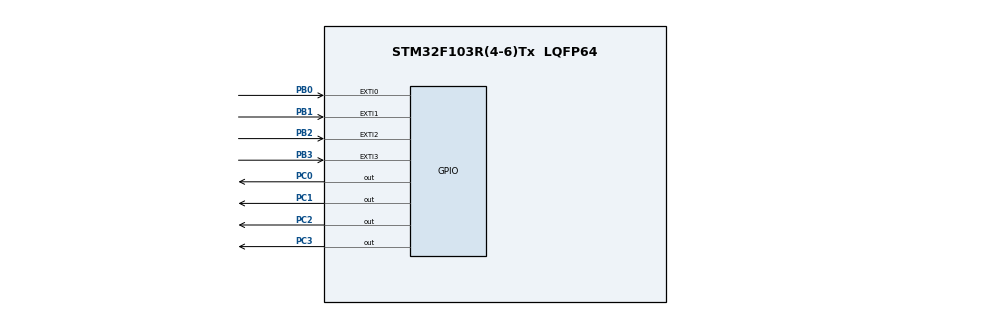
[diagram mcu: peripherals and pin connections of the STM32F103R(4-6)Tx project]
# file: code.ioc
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Mcu.Family=STM32F1
FREERTOS.Tasks01=defaultTask,24,128,StartDefaultTask,Default,NULL,Dynamic,NULL,NULL
PC2.Signal=GPIO_Output
NVIC.EXTI3_IRQn=true\:5\:0\:false\:false\:true\:true\:true\:true
PC0.GPIO_ModeDefaultOutputPP=GPIO_MODE_OUTPUT_PP
NVIC.TIM1_UP_IRQn=true\:0\:0\:false\:false\:true\:false\:false\:true
PC2.GPIO_Speed=GPIO_SPEED_FREQ_LOW
PB3.GPIO_ModeDefaultEXTI=GPIO_MODE_IT_RISING
PC0.Signal=GPIO_Output
VP_SYS_VS_ND.Mode=No_Debug
PC3.GPIO_Speed=GPIO_SPEED_FREQ_LOW
ProjectManager.StackSize=0x400
PC3.PinState=GPIO_PIN_RESET
VP_FREERTOS_VS_CMSIS_V2.Mode=CMSIS_V2
PB2.GPIO_ModeDefaultEXTI=GPIO_MODE_IT_RISING
NVIC.EXTI1_IRQn=true\:5\:0\:false\:false\:true\:true\:true\:true
PC0.GPIO_Speed=GPIO_SPEED_FREQ_LOW
ProjectManager.TargetToolchain=Makefile
PB1.GPIO_PuPd=GPIO_NOPULL
PB1.GPIO_ModeDefaultEXTI=GPIO_MODE_IT_RISING
PC3.Signal=GPIO_Output
PC1.PinState=GPIO_PIN_RESET
PB2.Signal=GPXTI2
board=custom
PC1.GPIO_PuPd=GPIO_PULLDOWN
PB0.GPIO_ModeDefaultEXTI=GPIO_MODE_IT_RISING
RCC.APB2Freq_Value=8000000
PB3.GPIO_PuPd=GPIO_NOPULL
VP_SYS_VS_tim1.Mode=TIM1
PC1.GPIO_Speed=GPIO_SPEED_FREQ_LOW
PC2.GPIO_PuPd=GPIO_PULLDOWN
Mcu.Name=STM32F103R(4-6)Tx
PB2.GPIO_PuPd=GPIO_NOPULL
PB3.Signal=GPXTI3
NVIC.EXTI0_IRQn=true\:5\:0\:true\:false\:true\:true\:true\:true
Mcu.Package=LQFP64
PB1.Signal=GPXTI1
NVIC.TimeBase=TIM1_UP_IRQn
PC2.PinState=GPIO_PIN_RESET
NVIC.TimeBaseIP=TIM1
ProjectManager.HeapSize=0x200
PC1.GPIO_ModeDefaultOutputPP=GPIO_MODE_OUTPUT_PP
NVIC.PriorityGroup=NVIC_PRIORITYGROUP_4
NVIC.EXTI2_IRQn=true\:5\:0\:false\:false\:true\:true\:true\:true
PC2.GPIO_ModeDefaultOutputPP=GPIO_MODE_OUTPUT_PP
PC3.GPIO_ModeDefaultOutputPP=GPIO_MODE_OUTPUT_PP
PC0.GPIO_PuPd=GPIO_PULLDOWN
RCC.APB1Freq_Value=8000000
PB0.Signal=GPXTI0
PC0.PinState=GPIO_PIN_RESET
PC1.Signal=GPIO_Output
PB0.GPIO_PuPd=GPIO_NOPULL
PC3.GPIO_PuPd=GPIO_PULLDOWN

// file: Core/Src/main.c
/* USER CODE BEGIN Header */
/**
  ******************************************************************************
  * @file           : main.c
  * @brief          : Main program body
  ******************************************************************************
  * @attention
  *
  * <h2><center>&copy; Copyright (c) 2020 STMicroelectronics.
  * All rights reserved.</center></h2>
  *
  * This software component is licensed by ST under Ultimate Liberty license
  * SLA0044, the "License"; You may not use this file except in compliance with
  * the License. You may obtain a copy of the License at:
  *                             www.st.com/SLA0044
  *
  ******************************************************************************
  */
/* USER CODE END Header */
#include "main.h"
#include "cmsis_os.h"
#include "gpio.h"

void SystemClock_Config(void);
void MX_FREERTOS_Init(void);

int main(void)
{

  /* MCU Configuration--------------------------------------------------------*/

  /* Reset of all peripherals, Initializes the Flash interface and the Systick. */
  HAL_Init();

  /* Configure the system clock */
  SystemClock_Config();

  /* Initialize all configured peripherals */
  MX_GPIO_Init();

  /* Init scheduler */
  osKernelInitialize();  /* Call init function for freertos objects (in freertos.c) */
  MX_FREERTOS_Init();
  /* Start scheduler */
  osKernelStart();

  /* We should never get here as control is now taken by the scheduler */
  /* Infinite loop */
  while (1)
  {

  }
}

void SystemClock_Config(void)
{
  RCC_OscInitTypeDef RCC_OscInitStruct = {0};
  RCC_ClkInitTypeDef RCC_ClkInitStruct = {0};

  /** Initializes the RCC Oscillators according to the specified parameters
  * in the RCC_OscInitTypeDef structure.
  */
  RCC_OscInitStruct.OscillatorType = RCC_OSCILLATORTYPE_HSI;
  RCC_OscInitStruct.HSIState = RCC_HSI_ON;
  RCC_OscInitStruct.HSICalibrationValue = RCC_HSICALIBRATION_DEFAULT;
  RCC_OscInitStruct.PLL.PLLState = RCC_PLL_NONE;
  if (HAL_RCC_OscConfig(&RCC_OscInitStruct) != HAL_OK)
  {
    Error_Handler();
  }
  /** Initializes the CPU, AHB and APB buses clocks
  */
  RCC_ClkInitStruct.ClockType = RCC_CLOCKTYPE_HCLK|RCC_CLOCKTYPE_SYSCLK
                              |RCC_CLOCKTYPE_PCLK1|RCC_CLOCKTYPE_PCLK2;
  RCC_ClkInitStruct.SYSCLKSource = RCC_SYSCLKSOURCE_HSI;
  RCC_ClkInitStruct.AHBCLKDivider = RCC_SYSCLK_DIV1;
  RCC_ClkInitStruct.APB1CLKDivider = RCC_HCLK_DIV1;
  RCC_ClkInitStruct.APB2CLKDivider = RCC_HCLK_DIV1;

  if (HAL_RCC_ClockConfig(&RCC_ClkInitStruct, FLASH_LATENCY_0) != HAL_OK)
  {
    Error_Handler();
  }
}

 /**
  * @brief  Period elapsed callback in non blocking mode
  * @note   This function is called  when TIM1 interrupt took place, inside
  * HAL_TIM_IRQHandler(). It makes a direct call to HAL_IncTick() to increment
  * a global variable "uwTick" used as application time base.
  * @param  htim : TIM handle
  * @retval None
  */
void HAL_TIM_PeriodElapsedCallback(TIM_HandleTypeDef *htim)
{
  if (htim->Instance == TIM1) {
    HAL_IncTick();
  }
}

void Error_Handler(void)
{
  __disable_irq();
  while (1)
  {
  }
}

/************************ (C) COPYRIGHT STMicroelectronics *****END OF FILE****/

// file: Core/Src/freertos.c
/* USER CODE BEGIN Header */
/**
  ******************************************************************************
  * File Name          : freertos.c
  * Description        : Code for freertos applications
  ******************************************************************************
  * @attention
  *
  * <h2><center>&copy; Copyright (c) 2020 STMicroelectronics.
  * All rights reserved.</center></h2>
  *
  * This software component is licensed by ST under Ultimate Liberty license
  * SLA0044, the "License"; You may not use this file except in compliance with
  * the License. You may obtain a copy of the License at:
  *                             www.st.com/SLA0044
  *
  ******************************************************************************
  */
/* USER CODE END Header */

#include "FreeRTOS.h"
#include "task.h"
#include "main.h"
#include "cmsis_os.h"

/* USER CODE BEGIN Includes */
#include "example.h"
/* USER CODE END Includes */

/* Definitions for defaultTask */
osThreadId_t defaultTaskHandle;
const osThreadAttr_t defaultTask_attributes = {
  .name = "defaultTask",
  .priority = (osPriority_t) osPriorityNormal,
  .stack_size = 128 * 4
};

void StartDefaultTask(void *argument);

void MX_FREERTOS_Init(void); /* (MISRA C 2004 rule 8.1) */

void MX_FREERTOS_Init(void) {
  /* USER CODE BEGIN Init */
  exampleInit();
  /* USER CODE END Init */

  /* Create the thread(s) */
  /* creation of defaultTask */
  xTaskCreate(StartDefaultTask, "StartDefaultTask", 128, NULL, 1, NULL);

}

void StartDefaultTask(void *argument)
{
  /* USER CODE BEGIN StartDefaultTask */
  /* Infinite loop */
  for(;;)
  {
    vTaskDelay(1000);
  }
  /* USER CODE END StartDefaultTask */
}

/************************ (C) COPYRIGHT STMicroelectronics *****END OF FILE****/
